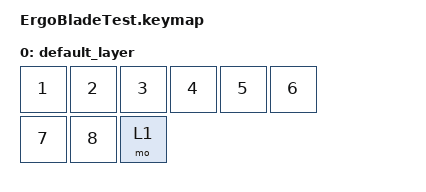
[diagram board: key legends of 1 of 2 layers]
#include <behaviors.dtsi>
#include <dt-bindings/zmk/keys.h>
#include <dt-bindings/zmk/bt.h>

/ {  
    keymap {
        compatible = "zmk,keymap";

        default_layer {
            bindings = <
                &kp N1  &kp N2     &kp N3     &kp N4  &kp N5     &kp N6
                &kp N7  &kp N8     &mo 1
            >;
        }; 
        num_layer {
            bindings = <
                &kp DOT  &kp N0 &bootloader
                &bt BT_SEL 0  &bt BT_SEL 1&bt BT_CLR
            >;
        };
    };
};
